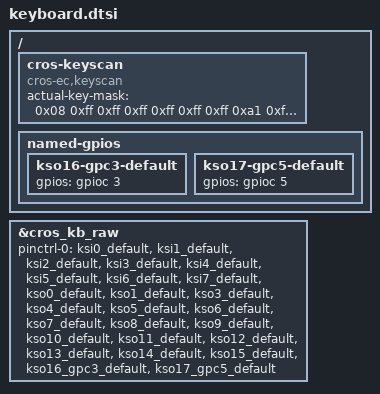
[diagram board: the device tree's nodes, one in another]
/* Copyright 2024 The ChromiumOS Authors
 * Use of this source code is governed by a BSD-style license that can be
 * found in the LICENSE file.
 */

/ {
	cros-keyscan {
		compatible = "cros-ec,keyscan";
		actual-key-mask = <
			0x08	/* C0 */
			0xff	/* C1 */
			0xff	/* C2 */
			0xff	/* C3 */
			0xff	/* C4 */
			0xff	/* C5 */
			0xff	/* C6 */
			0xa1	/* C7 */
			0xff	/* C8 */
			0xf7	/* C9 */
			0x01	/* C10 */
			0xff	/* C11 */
			0xff	/* C12 */
			0x40	/* C13 */
			0x0a	/* C14 */
			0x40	/* C15 */
			0x01	/* C16 */
			0xc4	/* C17 */
		>;
	};

	named-gpios {
		kso16-gpc3-default {
			gpios = <&gpioc 3 (GPIO_OPEN_DRAIN | GPIO_PULL_UP)>;
		};
		kso17-gpc5-default {
			gpios = <&gpioc 5 (GPIO_OPEN_DRAIN | GPIO_PULL_UP)>;
		};
	};
};


&cros_kb_raw {
	status = "okay";
	pinctrl-0 = <
		&ksi0_default
		&ksi1_default
		&ksi2_default
		&ksi3_default
		&ksi4_default
		&ksi5_default
		&ksi6_default
		&ksi7_default
		&kso0_default
		&kso1_default
		&kso3_default
		&kso4_default
		&kso5_default
		&kso6_default
		&kso7_default
		&kso8_default
		&kso9_default
		&kso10_default
		&kso11_default
		&kso12_default
		&kso13_default
		&kso14_default
		&kso15_default
		&kso16_gpc3_default
		&kso17_gpc5_default
	>;
	pinctrl-names = "default";
};
